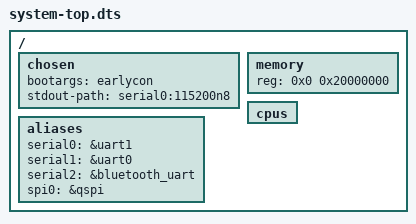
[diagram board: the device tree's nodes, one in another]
/*
 * CAUTION: This file is automatically generated by Xilinx.
 * Version:  
 * Today is: Sun Jul 29 15:49:07 2018
*/


/dts-v1/;
/include/ "zynq-7000.dtsi"
/include/ "pl.dtsi"
/include/ "pcw.dtsi"
/ {
	chosen {
		bootargs = "earlycon";
		stdout-path = "serial0:115200n8";
	};
	aliases {
		serial0 = &uart1;
		serial1 = &uart0;
		serial2 = &bluetooth_uart;
		spi0 = &qspi;
	};
	memory {
		device_type = "memory";
		reg = <0x0 0x20000000>;
	};
	cpus {
		/delete-node/ cpu@1 ;
	};
};
#include "system-user.dtsi"
